# STM32G081 register map
File version: 1.8
CPU: CM0 r0p1, little endian, MPU, no FPU, 2 interrupt priority bits
Registers are 32-bit, read-write, reset 0x0 unless marked. A register's access mark holds for its fields unless they carry their own. Offsets are from the block's base; [hi:lo] are bit positions; {n}, {i} and the like mark numbered series; 'fields as' and 'values as' point back to an identical list.

## RCC — Reset and clock control
Base 0x40021000
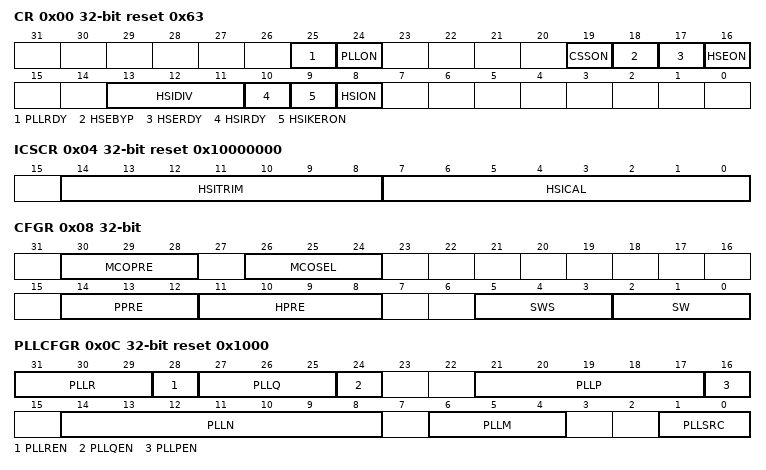
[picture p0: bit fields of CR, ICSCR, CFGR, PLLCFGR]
0x00 CR reset 0x63 — Clock control register
  [25] PLLRDY — PLL clock ready flag
    0=Unlocked (PLL unlocked); 1=Locked (PLL locked)
  [24] PLLON — PLL enable
    0=Disabled (PLL powered off); 1=Enabled (PLL enabled)
  [19] CSSON — Clock security system enable
    0=Disabled (HSE clock is not monitored); 1=Enabled (HSE clock monitor enabled when HSE is ready, otherwise disabled)
  [18] HSEBYP — HSE crystal oscillator bypass
    0=Crystal (HSE is a crystal oscillator or ceramic resonator); 1=ExtClock (HSE is driven by an external clock)
  [17] HSERDY — HSE clock ready flag
    0=NotReady (HSE oscillator not ready); 1=Ready (HSE oscillator ready)
  [16] HSEON — HSE clock enable
    0=Disabled (HSE oscillator powered off); 1=Enabled (HSE oscillator enabled)
  [13:11] HSIDIV — HSI16 clock division factor
    0=Div1 (Divide HSI16 by 1); 1=Div2 (Divide HSI16 by 2); 2=Div4 (Divide HSI16 by 4); 3=Div8 (Divide HSI16 by 8); 4=Div16 (Divide HSI16 by 16); 5=Div32 (Divide HSI16 by 32); 6=Div64 (Divide HSI16 by 64); 7=Div128 (Divide HSI16 by 128)
  [10] HSIRDY — HSI16 clock ready flag
    0=NotReady (HSI oscillator not ready); 1=Ready (HSI oscillator ready)
  [9] HSIKERON — HSI16 always enable for peripheral kernels
    0=NotForce (No effect on HSI16 oscillator); 1=Forced (HSI16 oscillator forced on even in Stop modes)
  [8] HSION — HSI16 clock enable
    0=Disabled (HSI oscillator powered off); 1=Enabled (HSI oscillator enabled)
0x04 ICSCR access per field reset 0x10000000 — Internal clock sources calibration register
  [14:8] HSITRIM rw — HSI16 clock trimming
  [7:0] HSICAL ro — HSI16 clock calibration
0x08 CFGR access per field — Clock configuration register
  [30:28] MCOPRE ro — Microcontroller clock output prescaler
    0=Div1 (Divide by 1); 1=Div2 (Divide by 2); 2=Div3 (Divide by 4); 3=Div8 (Divide by 8); 4=Div16 (Divide by 16); 5=Div32 (Divide by 32); 6=Div64 (Divide by 64); 7=Div128 (Divide by 128)
  [26:24] MCOSEL rw — Microcontroller clock output
    0=NoClock; 1=SYSCLK (SYSCLK clock selected); 3=HSI16 (HSI16 oscillator clock selected); 4=HSE (HSE oscillator clock selected); 5=PLLR (PLLRCLK clock selected); 6=LSI (LSI oscillator clock selected); 7=LSE (LSE oscillator clock selected)
  [14:12] PPRE rw — APB prescaler
    4=Div2 (Divide by 2); 5=Div4 (Divide by 4); 6=Div8 (Divide by 8); 7=Div16 (Divide by 16); other=Div1 (Divide by 1)
  [11:8] HPRE rw — AHB prescaler
    8=Div2 (Divide by 2); 9=Div4 (Divide by 4); 10=Div8 (Divide by 8); 11=Div16 (Divide by 16); 12=Div64 (Divide by 64); 13=Div128 (Divide by 128); 14=Div256 (Divide by 256); 15=Div512 (Divide by 512); other=Div1 (Divide by 1)
  [5:3] SWS ro — System clock switch status
    0=HSISYS (HSISYS clock selected); 1=HSE (HSE clock selected); 2=PLLR (PLLRCLK clock selected); 3=LSI (LSI clock selected); 4=LSE (LSE clock selected)
  [2:0] SW rw — System clock switch
    values as SWS
0x0C PLLCFGR reset 0x1000 — PLL configuration register
  [31:29] PLLR range 1..7 — PLL VCO division factor R for PLLRCLK clock output
  [28] PLLREN — PLLRCLK clock output enable
    0=Disabled (PLL output disabled (saves power)); 1=Enabled (PLL output enabled)
  [27:25] PLLQ range 1..7 — PLL VCO division factor Q for PLLQCLK clock output
  [24] PLLQEN — PLLQCLK clock output enable
    values as PLLREN
  [21:17] PLLP range 1..31 — PLL VCO division factor P for PLLPCLK clock output
  [16] PLLPEN — PLLPCLK clock output enable
    values as PLLREN
  [14:8] PLLN range 8..86 — PLL frequency multiplication factor N
  [6:4] PLLM — Division factor M of the PLL input clock divider
  [1:0] PLLSRC — PLL input clock source
    0=No clock selected (saves power); 2=HSI16 (HSI16 clock selected); 3=HSE (HSE clock selected)
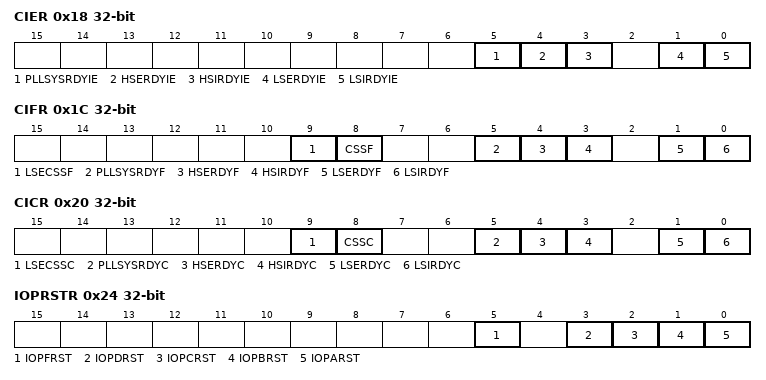
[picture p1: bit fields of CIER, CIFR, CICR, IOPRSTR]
0x18 CIER — Clock interrupt enable register
  [all] fields
    0=Disabled (Interrupt disabled); 1=Enabled (Interrupt enabled)
  [5] PLLSYSRDYIE — PLL ready interrupt enable
  [4] HSERDYIE — HSE ready interrupt enable
  [3] HSIRDYIE — HSI ready interrupt enable
  [1] LSERDYIE — LSE ready interrupt enable
  [0] LSIRDYIE — LSI ready interrupt enable
0x1C CIFR ro — Clock interrupt flag register
  [all] fields
    0=NotInterrupted (Interrupt not triggered); 1=Interrupted (Interrup triggered)
  [9] LSECSSF — LSE Clock security system interrupt flag
  [8] CSSF — Clock security system interrupt flag
  [5] PLLSYSRDYF — PLL ready interrupt flag
  [4] HSERDYF — HSE ready interrupt flag
  [3] HSIRDYF — HSI ready interrupt flag
  [1] LSERDYF — LSE ready interrupt flag
  [0] LSIRDYF — LSI ready interrupt flag
0x20 CICR wo — Clock interrupt clear register
  [all] fields
    1=Clear interrupt flag
  [9] LSECSSC — LSE Clock security system interrupt clear
  [8] CSSC — Clock security system interrupt clear
  [5] PLLSYSRDYC — PLL ready interrupt clear
  [4] HSERDYC — HSE ready interrupt clear
  [3] HSIRDYC — HSI ready interrupt clear
  [1] LSERDYC — LSE ready interrupt clear
  [0] LSIRDYC — LSI ready interrupt clear
0x24 IOPRSTR — GPIO reset register
  [all] fields
    1=Reset peripheral
  [5] IOPFRST — I/O port F reset
  [3] IOPDRST — I/O port D reset
  [2] IOPCRST — I/O port C reset
  [1] IOPBRST — I/O port B reset
  [0] IOPARST — I/O port A reset
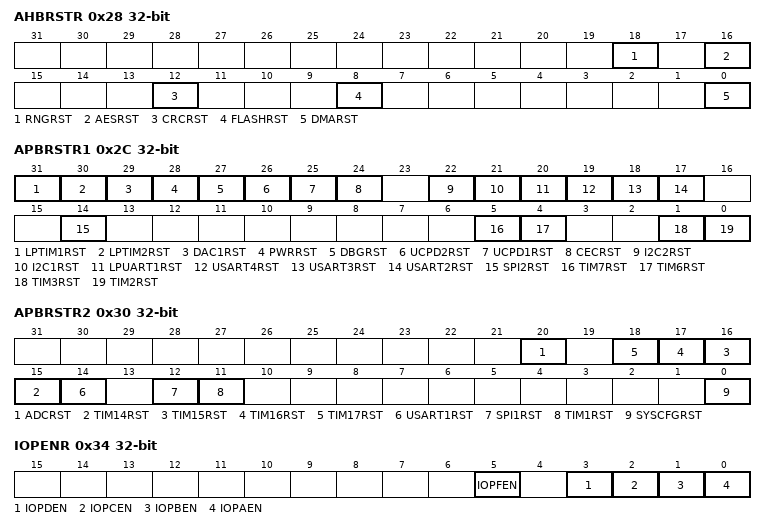
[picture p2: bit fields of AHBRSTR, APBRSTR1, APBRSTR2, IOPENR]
0x28 AHBRSTR — AHB peripheral reset register
  [all] fields
    1=Reset peripheral
  [18] RNGRST — Random number generator reset
  [16] AESRST — AES hardware accelerator reset
  [12] CRCRST — CRC reset
  [8] FLASHRST — FLITF reset
  [0] DMARST — DMA1 reset
0x2C APBRSTR1 — APB peripheral reset register 1
  [all] fields
    1=Reset peripheral
  [31] LPTIM1RST — Low Power Timer 1 reset
  [30] LPTIM2RST — Low Power Timer 2 reset
  [29] DAC1RST — DAC1 interface reset
  [28] PWRRST — Power interface reset
  [27] DBGRST — Debug support reset
  [26] UCPD2RST — UCPD2 reset
  [25] UCPD1RST — UCPD1 reset
  [24] CECRST — HDMI CEC reset
  [22] I2C2RST — I2C2 reset
  [21] I2C1RST — I2C1 reset
  [20] LPUART1RST — LPUART1 reset
  [19] USART4RST — USART4 reset
  [18] USART3RST — USART3 reset
  [17] USART2RST — USART2 reset
  [14] SPI2RST — SPI2 reset
  [5] TIM7RST — TIM7 timer reset
  [4] TIM6RST — TIM6 timer reset
  [1] TIM3RST — TIM3 timer reset
  [0] TIM2RST — TIM2 timer reset
0x30 APBRSTR2 — APB peripheral reset register 2
  [all] fields
    1=Reset peripheral
  [20] ADCRST — ADC reset
  [n+1] TIM{n}RST (n=14..17) — TIM{n} timer reset
  [14] USART1RST — USART1 reset
  [12] SPI1RST — SPI1 reset
  [11] TIM1RST — TIM1 timer reset
  [0] SYSCFGRST — SYSCFG, COMP and VREFBUF reset
0x34 IOPENR — GPIO clock enable register
  [all] fields
    0=Disabled (Peripheral disabled (typically saves power)); 1=Enabled (Peripheral enabled)
  [5] IOPFEN — I/O port F clock enable
  [3] IOPDEN — I/O port D clock enable
  [2] IOPCEN — I/O port C clock enable
  [1] IOPBEN — I/O port B clock enable
  [0] IOPAEN — I/O port A clock enable
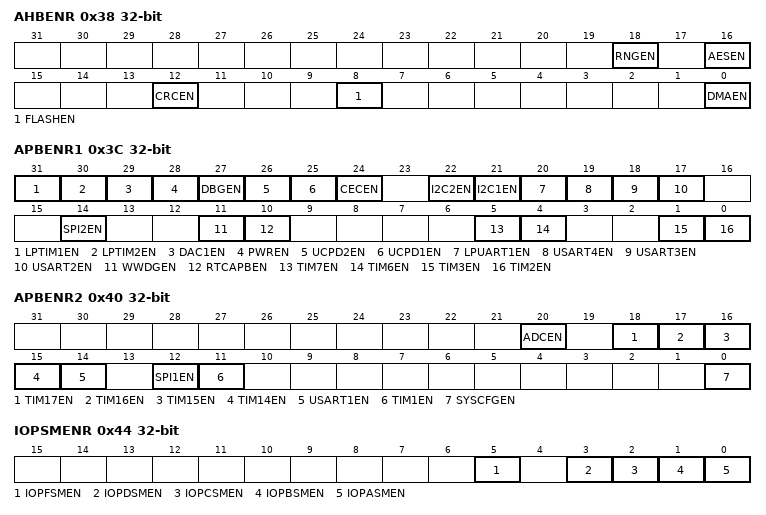
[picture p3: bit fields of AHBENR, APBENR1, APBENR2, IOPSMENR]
0x38 AHBENR — AHB peripheral clock enable register
  [all] fields
    values as the fields of IOPENR
  [18] RNGEN — Random number generator clock enable
  [16] AESEN — AES hardware accelerator
  [12] CRCEN — CRC clock enable
  [8] FLASHEN — Flash memory interface clock enable
  [0] DMAEN — DMA clock enable
0x3C APBENR1 — APB peripheral clock enable register 1
  [all] fields
    values as the fields of IOPENR
  [31] LPTIM1EN — LPTIM1 clock enable
  [30] LPTIM2EN — LPTIM2 clock enable
  [29] DAC1EN — DAC1 interface clock enable
  [28] PWREN — Power interface clock enable
  [27] DBGEN — Debug support clock enable
  [26] UCPD2EN — UCPD2 clock enable
  [25] UCPD1EN — UCPD1 clock enable
  [24] CECEN — HDMI CEC clock enable
  [22] I2C2EN — I2C2 clock enable
  [21] I2C1EN — I2C1 clock enable
  [20] LPUART1EN — LPUART1 clock enable
  [19] USART4EN — USART4 clock enable
  [18] USART3EN — USART3 clock enable
  [17] USART2EN — USART2 clock enable
  [14] SPI2EN — SPI2 clock enable
  [11] WWDGEN — WWDG clock enable
  [10] RTCAPBEN — RTC APB clock enable
  [5] TIM7EN — TIM7 timer clock enable
  [4] TIM6EN — TIM6 timer clock enable
  [1] TIM3EN — TIM3 timer clock enable
  [0] TIM2EN — TIM2 timer clock enable
0x40 APBENR2 — APB peripheral clock enable register 2
  [all] fields
    values as the fields of IOPENR
  [20] ADCEN — ADC clock enable
  [18] TIM17EN — TIM16 timer clock enable
  [17] TIM16EN — TIM16 timer clock enable
  [16] TIM15EN — TIM15 timer clock enable
  [15] TIM14EN — TIM14 timer clock enable
  [14] USART1EN — USART1 clock enable
  [12] SPI1EN — SPI1 clock enable
  [11] TIM1EN — TIM1 timer clock enable
  [0] SYSCFGEN — SYSCFG, COMP and VREFBUF clock enable
0x44 IOPSMENR — GPIO in Sleep mode clock enable register
  [all] fields
    values as the fields of IOPENR
  [5] IOPFSMEN — I/O port F clock enable during Sleep mode
  [3] IOPDSMEN — I/O port D clock enable during Sleep mode
  [2] IOPCSMEN — I/O port C clock enable during Sleep mode
  [1] IOPBSMEN — I/O port B clock enable during Sleep mode
  [0] IOPASMEN — I/O port A clock enable during Sleep mode
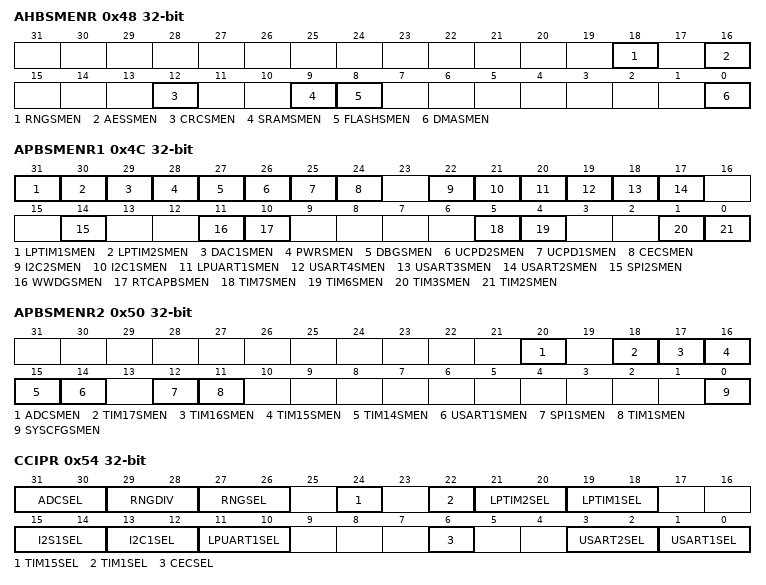
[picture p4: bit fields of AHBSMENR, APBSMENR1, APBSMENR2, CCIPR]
0x48 AHBSMENR — AHB peripheral clock enable in Sleep mode register
  [all] fields
    values as the fields of IOPENR
  [18] RNGSMEN — Random number generator clock enable during Sleep mode
  [16] AESSMEN — AES hardware accelerator clock enable during Sleep mode
  [12] CRCSMEN — CRC clock enable during Sleep mode
  [9] SRAMSMEN — SRAM clock enable during Sleep mode
  [8] FLASHSMEN — Flash memory interface clock enable during Sleep mode
  [0] DMASMEN — DMA clock enable during Sleep mode
0x4C APBSMENR1 — APB peripheral clock enable in Sleep mode register 1
  [all] fields
    values as the fields of IOPENR
  [31] LPTIM1SMEN — Low Power Timer 1 clock enable during Sleep mode
  [30] LPTIM2SMEN — Low Power Timer 2 clock enable during Sleep mode
  [29] DAC1SMEN — DAC1 interface clock enable during Sleep mode
  [28] PWRSMEN — Power interface clock enable during Sleep mode
  [27] DBGSMEN — Debug support clock enable during Sleep mode
  [26] UCPD2SMEN — UCPD2 clock enable during Sleep mode
  [25] UCPD1SMEN — UCPD1 clock enable during Sleep mode
  [24] CECSMEN — HDMI CEC clock enable during Sleep mode
  [22] I2C2SMEN — I2C2 clock enable during Sleep mode
  [21] I2C1SMEN — I2C1 clock enable during Sleep mode
  [20] LPUART1SMEN — LPUART1 clock enable during Sleep mode
  [19] USART4SMEN — USART4 clock enable during Sleep mode
  [18] USART3SMEN — USART3 clock enable during Sleep mode
  [17] USART2SMEN — USART2 clock enable during Sleep mode
  [14] SPI2SMEN — SPI2 clock enable during Sleep mode
  [11] WWDGSMEN — WWDG clock enable during Sleep mode
  [10] RTCAPBSMEN — RTC APB clock enable during Sleep mode
  [5] TIM7SMEN — TIM7 timer clock enable during Sleep mode
  [4] TIM6SMEN — TIM6 timer clock enable during Sleep mode
  [1] TIM3SMEN — TIM3 timer clock enable during Sleep mode
  [0] TIM2SMEN — TIM2 timer clock enable during Sleep mode
0x50 APBSMENR2 — APB peripheral clock enable in Sleep mode register 2
  [all] fields
    values as the fields of IOPENR
  [20] ADCSMEN — ADC clock enable during Sleep mode
  [18] TIM17SMEN — TIM16 timer clock enable during Sleep mode
  [17] TIM16SMEN — TIM16 timer clock enable during Sleep mode
  [16] TIM15SMEN — TIM15 timer clock enable during Sleep mode
  [15] TIM14SMEN — TIM14 timer clock enable during Sleep mode
  [14] USART1SMEN — USART1 clock enable during Sleep mode
  [12] SPI1SMEN — SPI1 clock enable during Sleep mode
  [11] TIM1SMEN — TIM1 timer clock enable during Sleep mode
  [0] SYSCFGSMEN — SYSCFG, COMP and VREFBUF clock enable during Sleep mode
0x54 CCIPR — Peripherals independent clock configuration register
  [31:30] ADCSEL — ADCs clock source selection
    0=SYSCLK (System clock selected); 1=PLLP (PLLPCLK clock selected); 2=HSI16 (HSI16 clock selected)
  [29:28] RNGDIV — Division factor of RNG clock divider
    0=Div1 (Divide by 1); 1=Div2 (Divide by 2); 2=Div4 (Divide by 4); 3=Div8 (Divide by 8)
  [27:26] RNGSEL — RNG clock source selection
    0=No clock selected; 1=HSI16 (HSI16 clock selected); 2=SYSCLK (SYSCLK clock selected); 3=PLLQ (PLLQCLK clock selected)
  [24] TIM15SEL — TIM15 clock source selection
    0=TIMP (TIMPCLK clock selected); 1=PLLQ (PLLQCLK clock selected)
  [22] TIM1SEL — TIM1 clock source selection
    values as TIM15SEL
  [21:20] LPTIM2SEL — LPTIM2 clock source selection
    0=PCLK (PCLK clock selected); 1=LSI (LSI clock selected); 2=HSI16 (HSI16 clock selected); 3=LSE (LSE clock selected)
  [19:18] LPTIM1SEL — LPTIM1 clock source selection
    values as LPTIM2SEL
  [15:14] I2S1SEL — I2S1 clock source selection
    0=SYSCLK (SYSCLK clock selected); 1=PLLP (PLLPCLK clock selected); 2=HSI16 (HSI16 clock selected); 3=CKIN (I2S_CKIN clock selected)
  [13:12] I2C1SEL — I2C1 clock source selection
    0=PCLK (PCLK clock selected); 1=SYSCLK (SYSCLK clock selected); 2=HSI16 (HSI16 clock selected)
  [11:10] LPUART1SEL — LPUART1 clock source selection
    0=PCLK (PCLK clock selected); 1=SYSCLK (SYSCLK clock selected); 2=HSI16 (HSI16 clock selected); 3=LSE (LSE clock selected)
  [6] CECSEL — HDMI CEC clock source selection
    0=HSI16 (HSI16 clock divided by 488 selected); 1=LSE (LSE clock selected)
  [3:2] USART2SEL — USART2 clock source selection
    values as LPUART1SEL
  [1:0] USART1SEL — USART1 clock source selection
    values as LPUART1SEL
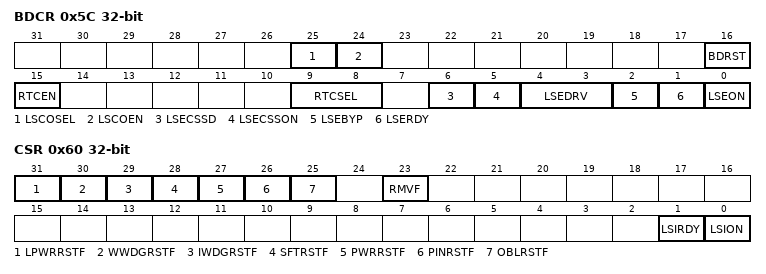
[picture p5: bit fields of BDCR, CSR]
0x5C BDCR — RTC domain control register
  [25] LSCOSEL — Low-speed clock output selection
    0=LSI (LSI clock selected); 1=LSE (LSE clock selected)
  [24] LSCOEN — Low-speed clock output (LSCO) enable
    0=Disabled (Low-speed clock output disabled); 1=Enabled (Low-speed clock output enabled)
  [16] BDRST — RTC domain software reset
    1=Reset (RTC domain software reset)
  [15] RTCEN — RTC clock enable
    0=Disabled (RTC disabled (saves power)); 1=Enabled (RTC enabled)
  [9:8] RTCSEL — RTC clock source selection
    0=No clock selected; 1=LSE (LSE clock selected); 2=LSI (LSI clock selected); 3=HSE32 (HSI clock divided by 32 selected)
  [6] LSECSSD — CSS on LSE failure Detection
    0=No failure detected; 1=Failure detected
  [5] LSECSSON — CSS on LSE enable
    0=Disabled (LSE clock is not monitored); 1=Enabled (LSE clock monitor enabled)
  [4:3] LSEDRV — LSE oscillator drive capability
    0=Low (Xtal mode lower driving capability); 1=MedLow (Xtal mode medium-low driving capability); 2=MedHigh (Xtal mode medium-high driving capability); 3=High (Xtal mode higher driving capability)
  [2] LSEBYP — LSE oscillator bypass
    0=Crystal (LSE is a crystal oscillator or ceramic resonator); 1=ExtClock (LSE is driven by an external clock)
  [1] LSERDY — LSE oscillator ready
    0=NotReady (LSE oscillator not ready); 1=Ready (LSE oscillator ready)
  [0] LSEON — LSE oscillator enable
    0=Disabled (LSE oscillator powered off); 1=Enabled (LSE oscillator enabled)
0x60 CSR — Control/status register
  [31] LPWRRSTF — Low-power reset flag
    0=NoReset (This reset type has not occurred); 1=Reset (This reset type has occurred)
  [30] WWDGRSTF — Window watchdog reset flag
    values as LPWRRSTF
  [29] IWDGRSTF — Independent window watchdog reset flag
    values as LPWRRSTF
  [28] SFTRSTF — Software reset flag
    values as LPWRRSTF
  [27] PWRRSTF — BOR or POR/PDR flag
    values as LPWRRSTF
  [26] PINRSTF — Pin reset flag
    values as LPWRRSTF
  [25] OBLRSTF — Option byte loader reset flag
    values as LPWRRSTF
  [23] RMVF — Remove reset flags
    1=Clear reset flags
  [1] LSIRDY — LSI oscillator ready
    0=NotReady (LSI oscillator not ready); 1=Ready (LSI oscillator ready)
  [0] LSION — LSI oscillator enable
    0=Disabled (LSI oscillator powered off); 1=Enabled (LSI oscillator enabled)
